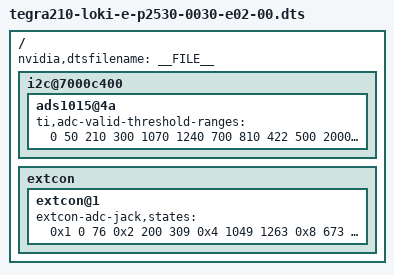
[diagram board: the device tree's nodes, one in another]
#include "tegra210-loki-e-p2530-0030-e01-00.dts"
#include "tegra210-platforms/tegra210-loki-rail-delay-p2530-0999-e02.dtsi"

/ {
	nvidia,dtsfilename = __FILE__;

	i2c@7000c400 {
		ads1015@4a {
			ti,adc-valid-threshold-ranges= <0     50
							210   300
							1070  1240
							700   810
							422   500
							2000  2047>;
		};
	};
	extcon {
		extcon@1 {
			extcon-adc-jack,states = <0x1    0     76
						  0x2    200   309
						  0x4    1049  1263
						  0x8    673   848
						  0x10   402   524>;
		};
	};
};
